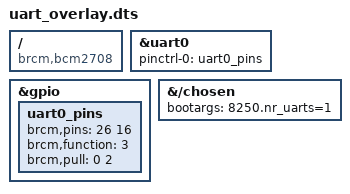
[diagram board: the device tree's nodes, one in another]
/dts-v1/;
/plugin/;

/{
    compatible = "brcm,bcm2708";

    fragment@0{
        target = <&uart0>;
        __overlay__{
            pinctrl-names = "default";
            pinctrl-0 = <&uart0_pins>;
            status = "okay";
        };
    };
    fragment@1{
        target = <&gpio>;
        __overlay__{
            uart0_pins: uart0_pins{
                brcm,pins =<26 16>;
                brcm,function = <3>;
                brcm,pull = <0 2>;
            };
        };
    };
    fragment@2{
        target-path = "/chosen";
        __overlay__{
            bootargs = "8250.nr_uarts=1"; 
        };
    };
    __overrides__ {
        txd0_pin = <&uart0_pins>,"brcm,pins:0";
        rxd0_pin = <&uart0_pins>,"brcm,pins:4";
    };

};


